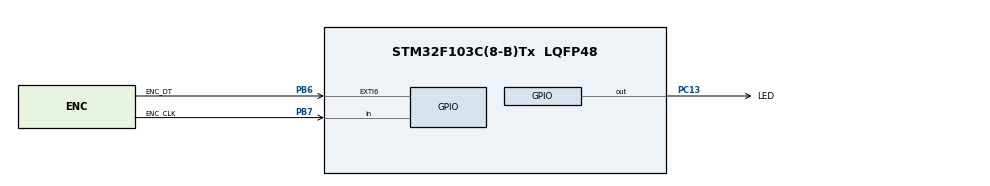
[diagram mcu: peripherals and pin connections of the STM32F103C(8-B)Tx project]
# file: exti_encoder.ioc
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Mcu.Family=STM32F1
Mcu.Name=STM32F103C(8-B)Tx
Mcu.Package=LQFP48
NVIC.EXTI9_5_IRQn=true\:0\:0\:false\:false\:true\:true\:true
NVIC.PriorityGroup=NVIC_PRIORITYGROUP_4
PA13.Mode=Serial_Wire
PA13.Signal=SYS_JTMS-SWDIO
PA14.Mode=Serial_Wire
PA14.Signal=SYS_JTCK-SWCLK
PB6.GPIO_Label=ENC_DT
PB6.Signal=GPXTI6
PB7.GPIO_Label=ENC_CLK
PB7.Signal=GPIO_Input
PC13-TAMPER-RTC.GPIO_Label=LED
PC13-TAMPER-RTC.Signal=GPIO_Output
PD0-OSC_IN.Mode=HSE-External-Oscillator
PD0-OSC_IN.Signal=RCC_OSC_IN
PD1-OSC_OUT.Mode=HSE-External-Oscillator
PD1-OSC_OUT.Signal=RCC_OSC_OUT
ProjectManager.HeapSize=0x200
ProjectManager.StackSize=0x400
ProjectManager.TargetToolchain=Makefile
RCC.AHBFreq_Value=72000000
RCC.APB1CLKDivider=RCC_HCLK_DIV2
RCC.APB1Freq_Value=36000000
RCC.APB1TimFreq_Value=72000000
RCC.APB2Freq_Value=72000000
RCC.APB2TimFreq_Value=72000000
RCC.HCLKFreq_Value=72000000
RCC.PLLMUL=RCC_PLL_MUL9
RCC.PLLSourceVirtual=RCC_PLLSOURCE_HSE
RCC.RTCClockSelection=RCC_RTCCLKSOURCE_LSE
RCC.SYSCLKFreq_VALUE=72000000
RCC.SYSCLKSource=RCC_SYSCLKSOURCE_PLLCLK
RCC.USBFreq_Value=48000000
RCC.USBPrescaler=RCC_USBCLKSOURCE_PLL_DIV1_5
board=custom

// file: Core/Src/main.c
/* USER CODE BEGIN Header */
/**
  ******************************************************************************
  * @file           : main.c
  * @brief          : Main program body
  ******************************************************************************
  * @attention
  *
  * <h2><center>&copy; Copyright (c) 2020 STMicroelectronics.
  * All rights reserved.</center></h2>
  *
  * This software component is licensed by ST under Ultimate Liberty license
  * SLA0044, the "License"; You may not use this file except in compliance with
  * the License. You may obtain a copy of the License at:
  *                             www.st.com/SLA0044
  *
  ******************************************************************************
  */
/* USER CODE END Header */
#include "main.h"
#include "gpio.h"

/* USER CODE BEGIN Includes */
// #include "ILI9341.h"
//
// #ifdef USE_LVGL
// #include "lvgl/lvgl.h"
// #include "lvgl_GUI.h"
// #include "lvgl_init_f103.h"
// #endif

#include "exti_encoder.h"

/* USER CODE END Includes */

void SystemClock_Config(void);
/* USER CODE BEGIN PFP */

#include "stdlib.h"
uint16_t random_int(int min, int max)
{
  return (uint16_t)rand() % max + min;
}

/* USER CODE END PFP */

int main(void)
{
  /* USER CODE BEGIN 1 */
#ifdef SEMIHOSTING_ENABLE
  initialise_monitor_handles();
#endif
  /* USER CODE END 1 */

  /* MCU Configuration--------------------------------------------------------*/

  /* Reset of all peripherals, Initializes the Flash interface and the Systick. */

  LL_APB2_GRP1_EnableClock(LL_APB2_GRP1_PERIPH_AFIO);
  LL_APB1_GRP1_EnableClock(LL_APB1_GRP1_PERIPH_PWR);

  NVIC_SetPriorityGrouping(NVIC_PRIORITYGROUP_4);

  /* System interrupt init*/

  /** NOJTAG: JTAG-DP Disabled and SW-DP Enabled
  */
  LL_GPIO_AF_Remap_SWJ_NOJTAG();

  /* Configure the system clock */
  SystemClock_Config();

  /* USER CODE BEGIN SysInit */
  ticks_init();
  /* USER CODE END SysInit */

  /* Initialize all configured peripherals */
  MX_GPIO_Init();
  /* USER CODE BEGIN 2 */
  /*---------Timer Encoder-------------*/
  EXTI_GPIO_Init();
  /* USER CODE END 2 */

  /* Infinite loop */
  /* USER CODE BEGIN WHILE */
  while (1)
  {
    delay_ms(100);
    /* USER CODE END WHILE */

  }
}

void SystemClock_Config(void)
{
  LL_FLASH_SetLatency(LL_FLASH_LATENCY_2);
  while(LL_FLASH_GetLatency()!= LL_FLASH_LATENCY_2)
  {
  }
  LL_RCC_HSE_Enable();

   /* Wait till HSE is ready */
  while(LL_RCC_HSE_IsReady() != 1)
  {

  }
  LL_RCC_PLL_ConfigDomain_SYS(LL_RCC_PLLSOURCE_HSE_DIV_1, LL_RCC_PLL_MUL_9);
  LL_RCC_PLL_Enable();

   /* Wait till PLL is ready */
  while(LL_RCC_PLL_IsReady() != 1)
  {

  }
  LL_RCC_SetAHBPrescaler(LL_RCC_SYSCLK_DIV_1);
  LL_RCC_SetAPB1Prescaler(LL_RCC_APB1_DIV_2);
  LL_RCC_SetAPB2Prescaler(LL_RCC_APB2_DIV_1);
  LL_RCC_SetSysClkSource(LL_RCC_SYS_CLKSOURCE_PLL);

   /* Wait till System clock is ready */
  while(LL_RCC_GetSysClkSource() != LL_RCC_SYS_CLKSOURCE_STATUS_PLL)
  {

  }
  LL_Init1msTick(72000000);
  LL_SetSystemCoreClock(72000000);
}

void Error_Handler(void)
{
  __disable_irq();
  while (1)
  {
  }
}
